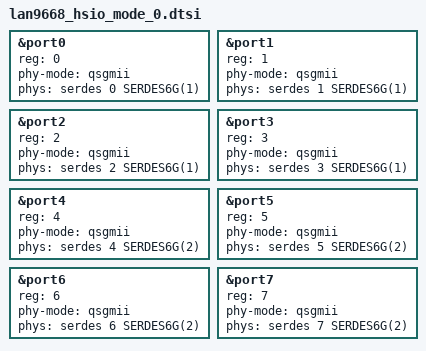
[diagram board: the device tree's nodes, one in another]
// SPDX-License-Identifier: (GPL-2.0+ OR MIT)

&port0 {
	reg = <0>;
	phy-mode = "qsgmii";
	phys = <&serdes 0 SERDES6G(1)>;
};

&port1 {
	reg = <1>;
	phy-mode = "qsgmii";
	phys = <&serdes 1 SERDES6G(1)>;
};

&port2 {
	reg = <2>;
	phy-mode = "qsgmii";
	phys = <&serdes 2 SERDES6G(1)>;
};

&port3 {
	reg = <3>;
	phy-mode = "qsgmii";
	phys = <&serdes 3 SERDES6G(1)>;
};

&port4 {
	reg = <4>;
	phy-mode = "qsgmii";
	phys = <&serdes 4 SERDES6G(2)>;
};

&port5 {
	reg = <5>;
	phy-mode = "qsgmii";
	phys = <&serdes 5 SERDES6G(2)>;
};

&port6 {
	reg = <6>;
	phy-mode = "qsgmii";
	phys = <&serdes 6 SERDES6G(2)>;
};

&port7 {
	reg = <7>;
	phy-mode = "qsgmii";
	phys = <&serdes 7 SERDES6G(2)>;
};
